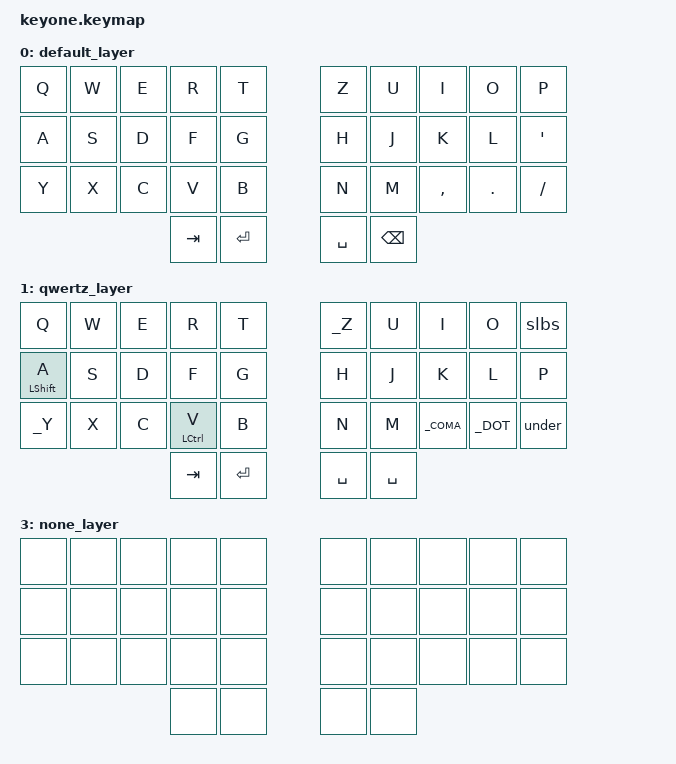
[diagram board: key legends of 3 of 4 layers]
// Copyright (c) 2022 The ZMK Contributors
// SPDX-License-Identifier: MIT

#include <behaviors.dtsi>
#include <dt-bindings/zmk/outputs.h>
#include <dt-bindings/zmk/keys.h>
#include <dt-bindings/zmk/bt.h>
#include "keys_de.h"

#define DEFAULT 0
#define QWER    1
#define SYML    2
#define NONE    3

/ {
    behaviors {
        ht: hold_tap {
            label = "hold_tap";
            compatible = "zmk,behavior-hold-tap";
            #binding-cells = <2>;
            flavor = "tap-preferred";
            tapping-term-ms = <220>;
            quick-tap-ms = <150>;
            global-quick-tap;
            bindings = <&kp>, <&kp>;
        };
        slbs: slash_backslash {
            compatible = "zmk,behavior-mod-morph";
            #binding-cells = <0>;
            bindings = <&kp _SLSH>, <&kp _BSLH>;
            mods = <(MOD_LSFT|MOD_RSFT)>;
        };
        under: under_minus {
            compatible = "zmk,behavior-mod-morph";
            #binding-cells = <0>;
            bindings = <&kp _UNDR>, <&kp _MINUS>;
            mods = <(MOD_LSFT|MOD_RSFT)>;
        };
    };
    combos {
        compatible = "zmk,combos";
        combo_toqwer {
            timeout-ms = <50>;
            key-positions = <0 1 2 3>;
            bindings = <&tog 1>;
            // layers = <0,1>;
        };
        // combo_bt_clear {
        //     timeout-ms = <50>;
        //     key-positions = <10 11 12 13>;
        //     bindings = <&bt BT_CLR>;
        //     // layers = <1>;
        // };
        combo_bt_clear_all {
            timeout-ms = <50>;
            key-positions = <11 12 13 14>;
            bindings = <&bt BT_CLR_ALL>;
            // layers = <1>;
        };
        // combo_bt_next {
        //     timeout-ms = <50>;
        //     key-positions = <20 21 22>;
        //     bindings = <&bt BT_NXT>;
        //     // layers = <1>;
        // };
        combo_bootloader {
            timeout-ms = <50>;
            key-positions = <1 2 3 4>;
            bindings = <&bootloader>;
            // layers = <1>;
        };
        combo_reset {
            timeout-ms = <50>;
            key-positions = <0 1 2 3 4>;
            bindings = <&sys_reset>;
            // layers = <1>;
        };
        combo_bluetooth_toggle {
            timeout-ms = <50>;
            // key-positions = <21 22 23>;
            key-positions = <10 11 12 13>;
            bindings = <&out OUT_BLE>;
        };

        // todo: use macro approach from website
        combo_esc {
            timeout-ms = <50>;
            key-positions = <12 13>;
            bindings = <&kp ESC>;
            layers = <1>;
        };
        combo_tab {
            timeout-ms = <50>;
            key-positions = <22 23>;
            bindings = <&kp TAB>;
            layers = <1>;
        };
        combo_bksp {
            timeout-ms = <50>;
            key-positions = <16 17>;
            bindings = <&kp BKSP>;
            layers = <1>;
        };
        combo_ret {
            timeout-ms = <50>;
            key-positions = <26 27>;
            bindings = <&kp RET>;
            layers = <1>;
        };
    };
    keymap {
        compatible = "zmk,keymap";
        default_layer {
            bindings = <
        //╭──────────┬──────────┬──────────┬──────────┬──────────╮   ╭──────────┬──────────┬──────────┬──────────┬──────────╮
        //│  Q       │  W       │  E       │  R       │  T       │   │  Z       │  U       │  I       │  O       │  P       │
            &kp Q      &kp W      &kp E      &kp R      &kp T          &kp Z      &kp U      &kp I      &kp O      &kp P
        //├──────────┼──────────┼──────────┼──────────┼──────────┤   ├──────────┼──────────┼──────────┼──────────┼──────────┤
        //│  A       │  S       │  D       │  F       │  G       │   │  H       │  J       │  K       │  L       │ '        │
            &kp A       &kp S      &kp D      &kp F      &kp G          &kp H      &kp J      &kp K      &kp L     &kp SQT
        //├──────────┼──────────┼──────────┼──────────┼──────────┤   ├──────────┼──────────┼──────────┼──────────┼──────────┤
        //│  Y       │  X       │  C       │  V       │  B       │   │  N       │  M       │ ,        │ .        │ /        │
            &kp Y      &kp X      &kp C      &kp V      &kp B          &kp N      &kp M      &kp COMMA  &kp DOT    &kp FSLH
        //╰──────────┴──────────┴──────────┼──────────┼──────────┤   ├──────────┼──────────┼──────────┴──────────┴──────────╯
                                             &kp TAB    &kp ENTER      &kp SPACE  &kp BSPC
        //                                 ╰──────────┴──────────╯   ╰──────────┴──────────╯
            >;
        };
        qwertz_layer {
            bindings = <
        //╭──────────┬──────────┬──────────┬──────────┬──────────╮   ╭──────────┬──────────┬──────────┬──────────┬──────────╮
        //│  Q       │  W       │  E       │  R       │  T       │   │  Z       │  U       │  I       │  O       │  /       │
            &kp Q      &kp W      &kp E      &kp R      &kp T          &kp _Z     &kp U      &kp I      &kp O      &slbs 
        //├──────────┼──────────┼──────────┼──────────┼──────────┤   ├──────────┼──────────┼──────────┼──────────┼──────────┤
        //│  A       │  S       │  D       │  F       │  G       │   │  H       │  J       │  K       │  L       │ P        │
          &ht LSHIFT A  &kp S      &kp D      &kp F      &kp G          &kp H      &kp J      &kp K      &kp L     &kp P 
        //├──────────┼──────────┼──────────┼──────────┼──────────┤   ├──────────┼──────────┼──────────┼──────────┼──────────┤
        //│  Y       │  X       │  C       │  V       │  B       │   │  N       │  M       │ ,        │ .        │ _        │
            &kp _Y      &kp X      &kp C   &ht LCTRL V   &kp B          &kp N      &kp M     &kp _COMA  &kp _DOT   &under
        //╰──────────┴──────────┴──────────┼──────────┼──────────┤   ├──────────┼──────────┼──────────┴──────────┴──────────╯
                                             &kp TAB    &kp ENTER      &kp SPACE  &kp SPACE
        //                                 ╰──────────┴──────────╯   ╰──────────┴──────────╯
            >;
        };
        symbols_left {
            bindings = <
        //╭──────────┬──────────┬──────────┬──────────┬──────────╮   ╭──────────┬──────────┬──────────┬──────────┬──────────╮
        //│          │          │          │          │          │   │  Z       │  U       │  I       │  O       │  /       │
            &trans      &trans     &trans     &trans     &trans         &kp _Z     &kp U      &kp I      &kp O      &kp _SLSH 
        //├──────────┼──────────┼──────────┼──────────┼──────────┤   ├──────────┼──────────┼──────────┼──────────┼──────────┤
        //│  <       │  [       │  {       │  (       │  ^       │   │  H       │  J       │  K       │  L       │ P        │
            &kp _LT     &kp _LBKT  &kp _LBRC  &kp _LPAR  &kp _CAET      &kp H      &kp J      &kp K      &kp L     &kp P 
        //├──────────┼──────────┼──────────┼──────────┼──────────┤   ├──────────┼──────────┼──────────┼──────────┼──────────┤
        //│  >       │  ]       │  }       │  )       │  #       │   │  N       │  M       │ ,        │ .        │ _        │
            &kp _GT     &kp _RBKT  &kp _RBRC  &mt _RPAR  _HASH          &kp N      &kp M     &kp _COMA  &kp _DOT   &kp _UNDR
        //╰──────────┴──────────┴──────────┼──────────┼──────────┤   ├──────────┼──────────┼──────────┴──────────┴──────────╯
                                             &trans     &trans         &kp SPACE  &kp SPACE
        //                                 ╰──────────┴──────────╯   ╰──────────┴──────────╯
            >;
        };
        none_layer {
            bindings = <
        //╭──────────┬──────────┬──────────┬──────────┬──────────╮   ╭──────────┬──────────┬──────────┬──────────┬──────────╮
        //│  Q       │  W       │  E       │  R       │  T       │   │  Z       │  U       │  I       │  O       │  /       │
            &none       &none      &none      &none      &none          &none      &none      &none      &none      &none 
        //├──────────┼──────────┼──────────┼──────────┼──────────┤   ├──────────┼──────────┼──────────┼──────────┼──────────┤
        //│  A       │  S       │  D       │  F       │  G       │   │  H       │  J       │  K       │  L       │ P        │
            &none       &none      &none      &none      &none          &none      &none      &none      &none     &none 
        //├──────────┼──────────┼──────────┼──────────┼──────────┤   ├──────────┼──────────┼──────────┼──────────┼──────────┤
        //│  Y       │  X       │  C       │  V       │  B       │   │  N       │  M       │ ,        │ .        │ _        │
            &none       &none      &none      &none      &none          &none      &none     &none      &none      &none
        //╰──────────┴──────────┴──────────┼──────────┼──────────┤   ├──────────┼──────────┼──────────┴──────────┴──────────╯
                                              &none      &none          &none      &none 
        //                                 ╰──────────┴──────────╯   ╰──────────┴──────────╯
            >;
        };
    };
};
